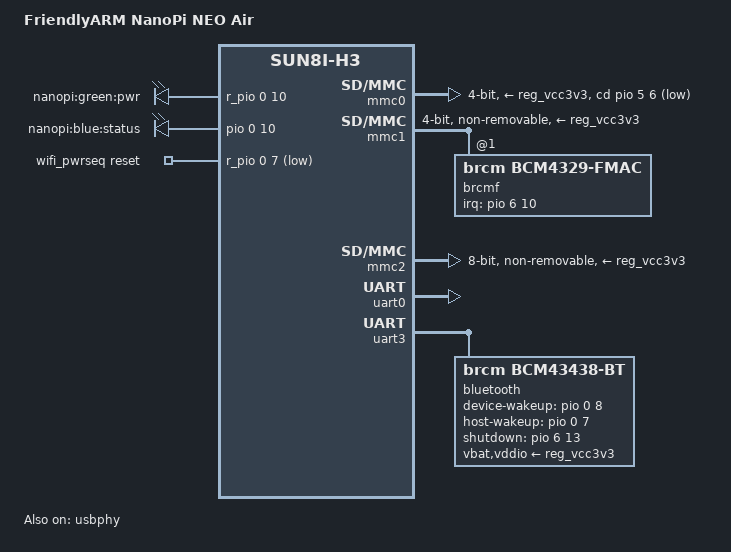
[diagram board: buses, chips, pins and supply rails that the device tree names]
/dts-v1/;
#include "sun8i-h3.dtsi"
#include "sunxi-common-regulators.dtsi"
#include <dt-bindings/gpio/gpio.h>
/ {
	model = "FriendlyARM NanoPi NEO Air";
	compatible = "friendlyarm,nanopi-neo-air", "allwinner,sun8i-h3";
	aliases {
		serial0 = &uart0;
	};
	chosen {
		stdout-path = "serial0:115200n8";
	};
	leds {
		compatible = "gpio-leds";
		led-0 {
			label = "nanopi:green:pwr";
			gpios = <&r_pio 0 10 GPIO_ACTIVE_HIGH>;  
			default-state = "on";
		};
		led-1 {
			label = "nanopi:blue:status";
			gpios = <&pio 0 10 GPIO_ACTIVE_HIGH>;  
		};
	};
	wifi_pwrseq: wifi_pwrseq {
		compatible = "mmc-pwrseq-simple";
		reset-gpios = <&r_pio 0 7 GPIO_ACTIVE_LOW>;  
	};
};
&mmc0 {
	vmmc-supply = <&reg_vcc3v3>;
	bus-width = <4>;
	cd-gpios = <&pio 5 6 GPIO_ACTIVE_LOW>;  
	status = "okay";
};
&mmc1 {
	vmmc-supply = <&reg_vcc3v3>;
	vqmmc-supply = <&reg_vcc3v3>;
	mmc-pwrseq = <&wifi_pwrseq>;
	bus-width = <4>;
	non-removable;
	status = "okay";
	brcmf: bcrmf@1 {
		reg = <1>;
		compatible = "brcm,bcm4329-fmac";
		interrupt-parent = <&pio>;
		interrupts = <6 10 IRQ_TYPE_LEVEL_LOW>;  
		interrupt-names = "host-wake";
	};
};
&mmc2 {
	pinctrl-names = "default";
	pinctrl-0 = <&mmc2_8bit_pins>;
	vmmc-supply = <&reg_vcc3v3>;
	vqmmc-supply = <&reg_vcc3v3>;
	bus-width = <8>;
	non-removable;
	status = "okay";
};
&uart0 {
	pinctrl-names = "default";
	pinctrl-0 = <&uart0_pa_pins>;
	status = "okay";
};
&uart3 {
	pinctrl-names = "default";
	pinctrl-0 = <&uart3_pins>, <&uart3_rts_cts_pins>;
	uart-has-rtscts;
	status = "okay";
	bluetooth {
		compatible = "brcm,bcm43438-bt";
		clocks = <&rtc CLK_OSC32K_FANOUT>;
		clock-names = "lpo";
		vbat-supply = <&reg_vcc3v3>;
		vddio-supply = <&reg_vcc3v3>;
		device-wakeup-gpios = <&pio 0 8 GPIO_ACTIVE_HIGH>;  
		host-wakeup-gpios = <&pio 0 7 GPIO_ACTIVE_HIGH>;  
		shutdown-gpios = <&pio 6 13 GPIO_ACTIVE_HIGH>;  
	};
};
&usbphy {
	status = "okay";
};
